# STM32MP13xx register map
File version: 1.5
CPU: CA7 r0p0, little endian, MPU, FPU, 4 interrupt priority bits
Registers are 32-bit, read-write, reset 0x0 unless marked. A register's access mark holds for its fields unless they carry their own. Offsets are from the block's base; [hi:lo] are bit positions; {n}, {i} and the like mark numbered series; 'fields as' and 'values as' point back to an identical list.

## TIM2
Base 0x40000000
Same registers: TIM3 0x40001000, TIM4 0x40002000, TIM5 0x40003000
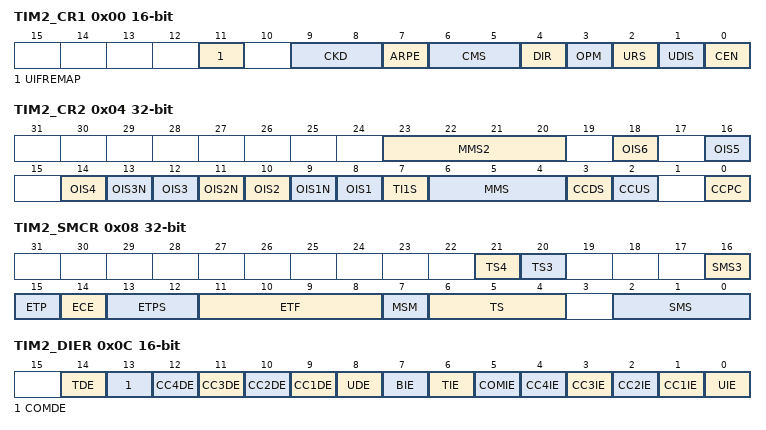
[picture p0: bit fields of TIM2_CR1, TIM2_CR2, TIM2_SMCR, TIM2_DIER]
0x00 TIM2_CR1 16-bit — TIM2 control register 1
  [11] UIFREMAP, [9:8] CKD, [7] ARPE, [6:5] CMS, [4] DIR, [3] OPM, [2] URS, [1] UDIS, [0] CEN
0x04 TIM2_CR2 — TIM2 control register 2
  [23:20] MMS2, [2n+6] OIS{n} (n=1..6), [13] OIS3N, [11] OIS2N, [9] OIS1N, [7] TI1S, [6:4] MMS, [3] CCDS, [2] CCUS, [0] CCPC
0x08 TIM2_SMCR — TIM2 slave mode control register
  [21] TS4, [20] TS3, [16] SMS3, [15] ETP, [14] ECE, [13:12] ETPS, [11:8] ETF, [7] MSM, [6:4] TS, [2:0] SMS
0x0C TIM2_DIER 16-bit — TIM2 DMA/interrupt enable register
  [14] TDE, [13] COMDE, [n+8] CC{n}DE (n=1..4), [8] UDE, [7] BIE, [6] TIE, [5] COMIE, [n] CC{n}IE (n=1..4), [0] UIE
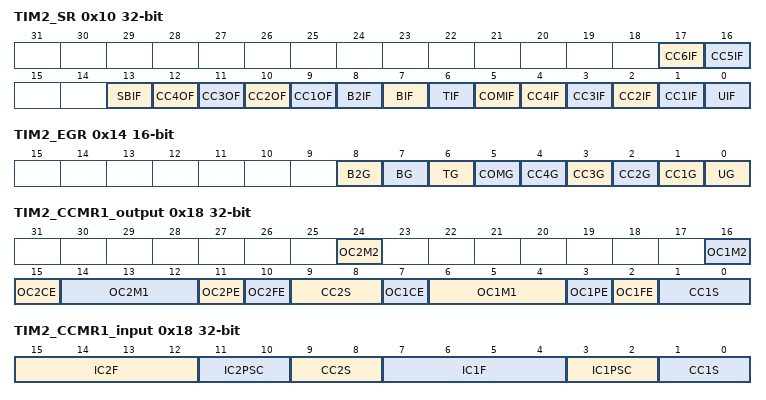
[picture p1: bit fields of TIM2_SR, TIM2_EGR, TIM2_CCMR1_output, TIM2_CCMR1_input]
0x10 TIM2_SR — TIM2 status register
  [17] CC6IF, [16] CC5IF, [13] SBIF, [n+8] CC{n}OF (n=1..4), [8] B2IF, [7] BIF, [6] TIF, [5] COMIF, [n] CC{n}IF (n=1..4), [0] UIF
0x14 TIM2_EGR 16-bit wo — TIM2 event generation register
  [8] B2G, [7] BG, [6] TG, [5] COMG, [n] CC{n}G (n=1..4), [0] UG
0x18 TIM2_CCMR1_output — The same register can be used for input capture mode (this section) or for output compare mode (next section). The direction of a channel is defined by configuring the corresponding CCxS bits. All the other bits of this register have a different function for input capture and for output compare modes. It is possible to combine both modes independently (e.g. channel 1 in input capture mode and channel 2 in output compare mode). Input capture mode:
  [24] OC2M2 — Output compare 2 mode refer to OC1M description on bits 6:4
  [16] OC1M2 — Output compare 1 mode These bits define the behavior of the output reference signal OC1REF from which OC1 and OC1N are derived. OC1REF is active high whereas OC1 and OC1N active level depends on CC1P and CC1NP bits. Note: In PWM mode, the OCREF level changes only when the result of the comparison changes or when the output compare mode switches from âfrozenâ mode to âPWMâ mode. Note: The OC1M[3] bit is not contiguous, located in bit 16.
    0=Frozen - The comparison between the output compare register TIMx_CCR1 and the counter TIMx_CNT has no effect on the outputs.(this mode is used to generate a timing base); 1=Set channel 1 to active level on match. OC1REF signal is forced high when the counter TIMx_CNT matches the capture/compare register 1 (TIMx_CCR1).; 2=Set channel 1 to inactive level on match. OC1REF signal is forced low when the counter TIMx_CNT matches the capture/compare register 1 (TIMx_CCR1).; 3=Toggle - OC1REF toggles when TIMx_CNT=TIMx_CCR1; 4=Force inactive level - OC1REF is forced low; 5=Force active level - OC1REF is forced high; 6=PWM mode 1 - In upcounting, channel 1 is active as long as TIMx_CNT<TIMx_CCR1 else inactive. In downcounting, channel 1 is inactive (OC1REF='0) as long as TIMx_CNT>TIMx_CCR1 else active (OC1REF=1).; 7=PWM mode 2 - In upcounting, channel 1 is inactive as long as TIMx_CNT<TIMx_CCR1 else active. In downcounting, channel 1 is active as long as TIMx_CNT>TIMx_CCR1 else inactive.; 8=Retriggerable OPM mode 1 - In up-counting mode, the channel is active until a trigger event is detected (on TRGI signal). Then, a comparison is performed as in PWM mode 1 and the channels becomes inactive again at the next update. In down-counting mode, the channel is inactive until a trigger event is detected (on TRGI signal). Then, a comparison is performed as in PWM mode 1 and the channels becomes inactive again at the next update.; 9=Retriggerable OPM mode 2 - In up-counting mode, the channel is inactive until a trigger event is detected (on TRGI signal). Then, a comparison is performed as in PWM mode 2 and the channels becomes inactive again at the next update. In down-counting mode, the channel is active until a trigger event is detected (on TRGI signal). Then, a comparison is performed as in PWM mode 1 and the channels becomes active again at the next update.; 12=Combined PWM mode 1 - OC1REF has the same behavior as in PWM mode 1. OC1REFC is the logical OR between OC1REF and OC2REF.; 13=Combined PWM mode 2 - OC1REF has the same behavior as in PWM mode 2. OC1REFC is the logical AND between OC1REF and OC2REF.; 14=Asymmetric PWM mode 1 - OC1REF has the same behavior as in PWM mode 1. OC1REFC outputs OC1REF when the counter is counting up, OC2REF when it is counting down.; 15=Asymmetric PWM mode 2 - OC1REF has the same behavior as in PWM mode 2. OC1REFC outputs OC1REF when the counter is counting up, OC2REF when it is counting down.
  [15] OC2CE — Output compare 2 clear enable
  [14:12] OC2M1 — Output compare 2 mode refer to OC1M description on bits 6:4
  [11] OC2PE — Output compare 2 preload enable
  [10] OC2FE — Output compare 2 fast enable
  [9:8] CC2S — Capture/Compare 2 selection This bit-field defines the direction of the channel (input/output) as well as the used input. Note: CC2S bits are writable only when the channel is OFF (CC2E = 0 in TIMx_CCER).
    0=CC2 channel is configured as output; 1=CC2 channel is configured as input, IC2 is mapped on TI2; 2=CC2 channel is configured as input, IC2 is mapped on TI1; 3=CC2 channel is configured as input, IC2 is mapped on TRC. This mode is working only if an internal trigger input is selected through the TS bit (TIMx_SMCR register)
  [7] OC1CE — Output compare 1 clear enable
    0=OC1Ref is not affected by the ETRF input; 1=OC1Ref is cleared as soon as a High level is detected on ETRF input
  [6:4] OC1M1 — Output compare 1 mode These bits define the behavior of the output reference signal OC1REF from which OC1 and OC1N are derived. OC1REF is active high whereas OC1 and OC1N active level depends on CC1P and CC1NP bits. Note: In PWM mode, the OCREF level changes only when the result of the comparison changes or when the output compare mode switches from âfrozenâ mode to âPWMâ mode. Note: The OC1M[3] bit is not contiguous, located in bit 16.
    values as OC1M2
  [3] OC1PE — Output compare 1 preload enable Note: The PWM mode can be used without validating the preload register only in one-pulse mode (OPM bit set in TIMx_CR1 register). Else the behavior is not guaranteed.
    0=Preload register on TIMx_CCR1 disabled. TIMx_CCR1 can be written at anytime, the new value is taken in account immediately.; 1=Preload register on TIMx_CCR1 enabled. Read/Write operations access the preload register. TIMx_CCR1 preload value is loaded in the active register at each update event.
  [2] OC1FE — Output compare 1 fast enable This bit decreases the latency between a trigger event and a transition on the timer output. It must be used in one-pulse mode (OPM bit set in TIMx_CR1 register), to have the output pulse starting as soon as possible after the starting trigger.
    0=CC1 behaves normally depending on counter and CCR1 values even when the trigger is ON. The minimum delay to activate CC1 output when an edge occurs on the trigger input is 5 clock cycles.; 1=An active edge on the trigger input acts like a compare match on CC1 output. Then, OC is set to the compare level independently from the result of the comparison. Delay to sample the trigger input and to activate CC1 output is reduced to 3 clock cycles. OCFE acts only if the channel is configured in PWM1 or PWM2 mode.
  [1:0] CC1S — Capture/Compare 1 selection This bit-field defines the direction of the channel (input/output) as well as the used input. Note: CC1S bits are writable only when the channel is OFF (CC1E = 0 in TIMx_CCER).
    0=CC1 channel is configured as output; 1=CC1 channel is configured as input, IC1 is mapped on TI1; 2=CC1 channel is configured as input, IC1 is mapped on TI2; 3=CC1 channel is configured as input, IC1 is mapped on TRC. This mode is working only if an internal trigger input is selected through TS bit (TIMx_SMCR register)
0x18 TIM2_CCMR1_input (alternate view of TIM2_CCMR1_output) — The same register can be used for input capture mode (this section) or for output compare mode (next section). The direction of a channel is defined by configuring the corresponding CCxS bits. All the other bits of this register have a different function for input capture and for output compare modes. It is possible to combine both modes independently (e.g. channel 1 in input capture mode and channel 2 in output compare mode). Input capture mode:
  [15:12] IC2F, [11:10] IC2PSC, [9:8] CC2S, [7:4] IC1F, [3:2] IC1PSC, [1:0] CC1S
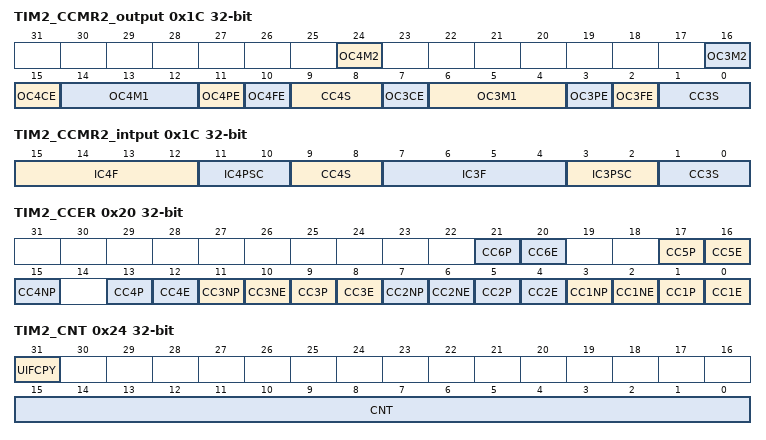
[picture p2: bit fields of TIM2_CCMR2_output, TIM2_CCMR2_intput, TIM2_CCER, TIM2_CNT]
0x1C TIM2_CCMR2_output — The same register can be used for input capture mode (this section) or for output compare mode (next section). The direction of a channel is defined by configuring the corresponding CCxS bits. All the other bits of this register have a different function for input capture and for output compare modes. It is possible to combine both modes independently (e.g. channel 1 in input capture mode and channel 2 in output compare mode). Input capture mode:
  [24] OC4M2 — Output compare 4 mode Refer to OC1M description (bits 6:4 in TIMx_CCMR1 register)
  [16] OC3M2 — Output compare 3 mode Refer to OC1M description (bits 6:4 in TIMx_CCMR1 register)
  [15] OC4CE — Output compare 4 clear enable
  [14:12] OC4M1 — Output compare 4 mode Refer to OC1M description (bits 6:4 in TIMx_CCMR1 register)
  [11] OC4PE — Output compare 4 preload enable
  [10] OC4FE — Output compare 4 fast enable
  [9:8] CC4S — Capture/Compare 4 selection This bit-field defines the direction of the channel (input/output) as well as the used input. Note: CC4S bits are writable only when the channel is OFF (CC4E = 0 in TIMx_CCER).
    0=CC4 channel is configured as output; 1=CC4 channel is configured as input, IC4 is mapped on TI4; 2=CC4 channel is configured as input, IC4 is mapped on TI3; 3=CC4 channel is configured as input, IC4 is mapped on TRC. This mode is working only if an internal trigger input is selected through TS bit (TIMx_SMCR register)
  [7] OC3CE — Output compare 3 clear enable
  [6:4] OC3M1 — Output compare 3 mode Refer to OC1M description (bits 6:4 in TIMx_CCMR1 register)
  [3] OC3PE — Output compare 3 preload enable
  [2] OC3FE — Output compare 3 fast enable
  [1:0] CC3S — Capture/Compare 3 selection This bit-field defines the direction of the channel (input/output) as well as the used input. Note: CC3S bits are writable only when the channel is OFF (CC3E = 0 in TIMx_CCER).
    0=CC3 channel is configured as output; 1=CC3 channel is configured as input, IC3 is mapped on TI3; 2=CC3 channel is configured as input, IC3 is mapped on TI4; 3=CC3 channel is configured as input, IC3 is mapped on TRC. This mode is working only if an internal trigger input is selected through TS bit (TIMx_SMCR register)
0x1C TIM2_CCMR2_intput (alternate view of TIM2_CCMR2_output) — The same register can be used for input capture mode (this section) or for output compare mode (next section). The direction of a channel is defined by configuring the corresponding CCxS bits. All the other bits of this register have a different function for input capture and for output compare modes. It is possible to combine both modes independently (e.g. channel 1 in input capture mode and channel 2 in output compare mode). Input capture mode:
  [15:12] IC4F, [11:10] IC4PSC, [9:8] CC4S, [7:4] IC3F, [3:2] IC3PSC, [1:0] CC3S
0x20 TIM2_CCER — TIM2 capture/compare enable register
  [4n-3] CC{n}P (n=1..6), [4n-4] CC{n}E (n=1..6), [4n-1] CC{n}NP (n=1..4), [10] CC3NE, [6] CC2NE, [2] CC1NE
0x24 TIM2_CNT access per field — TIM2 counter
  [31] UIFCPY ro, [15:0] CNT rw
0x28 TIM2_PSC 16-bit — TIM2 prescaler
0x2C TIM2_ARR 16-bit reset 0xFFFF — TIM2 auto-reload register
{0x30+4i} TIM2_CCR{i} 16-bit (i=1..4) — TIM2 capture/compare register {i}
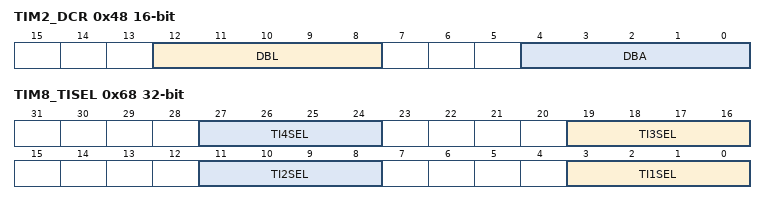
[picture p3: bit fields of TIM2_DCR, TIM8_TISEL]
0x48 TIM2_DCR 16-bit — TIM2 DMA control register
  [12:8] DBL, [4:0] DBA
0x4C TIM2_DMAR — TIM2 DMA address for full transfer
  [31:0] DMAB
0x60 TIM2_AF1 reset 0x1
  [17:14] ETRSEL — ETR source selection These bits select the ETR input source. Others: Reserved Note: These bits can not be modified as long as LOCK level 1 has been programmed (LOCK bits in TIMx_BDTR register).
    0=ETR input is connected to I/O; 3=ADC1 AWD1; 4=ADC1 AWD2; 5=ADC1 AWD3; 6=ADC2 AWD1; 7=ADC2 AWD2; 8=ADC2 AWD3
0x68 TIM8_TISEL
  [8n-5:8n-8] TI{n}SEL (n=1..4) — selects TI{n}[0] to TI{n}[15] input Others: Reserved
    0=TIM8_CH{n} input
